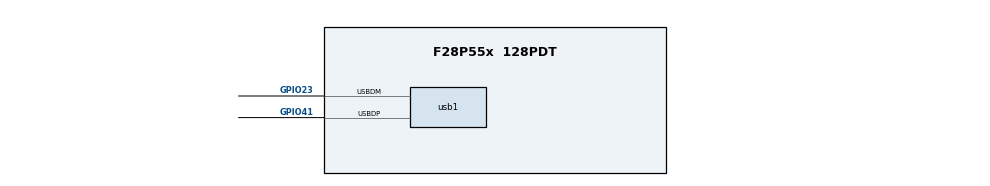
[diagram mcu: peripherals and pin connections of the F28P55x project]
/**
 * @cliArgs --device "F28P55x" --package "128PDT" --part "F28P55x_128PDT" --product "C2000WARE@5.02.00.00"
 * @versions {"tool":"1.13.0+2411"}
 */

/**
 * Import the modules used in this configuration.
 */
const usb  = scripting.addModule("/driverlib/usb.js", {}, false);
const usb1 = usb.addInstance();

/**
 * Write custom configuration values to the imported modules.
 */
usb1.$name                  = "myUSB0";
usb1.registerInterrupts     = true;
usb1.usb.$assign            = "USB0";
usb1.usb.usbdmPin.$assign   = "GPIO23";
usb1.usb.usbdpPin.$assign   = "GPIO41";
usb1.usbLib.usb_mode        = "Host";
usb1.dmQual.$name           = "myGPIOQUAL0";
usb1.dpQual.$name           = "myGPIOQUAL1";
usb1.USBInt.enableInterrupt = true;
